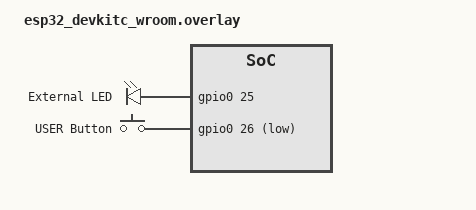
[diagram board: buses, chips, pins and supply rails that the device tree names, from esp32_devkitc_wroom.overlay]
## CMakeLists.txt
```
# SPDX-License-Identifier: Apache-2.0

cmake_minimum_required(VERSION 3.20.0)
find_package(Zephyr REQUIRED HINTS $ENV{ZEPHYR_BASE})
project(dronetag_task)

zephyr_include_directories(src)

target_sources(app PRIVATE 
            src/main.c
            src/my_led.c
            src/my_btn.c
            src/my_msgq.c
            src/my_fifo.c
            src/my_linked_list.c)
```

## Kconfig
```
# Config options for logger sample app

# Copyright (c) 2018 Nordic Semiconductor ASA
# SPDX-License-Identifier: Apache-2.0

mainmenu "Zephyr Application"

menu "Dronetag task configuration"

config MSGQ_SIZE
    int "Message Queue Size"
    default 10

endmenu

source "Kconfig.zephyr"
```

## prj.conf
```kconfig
CONFIG_PRINTK=y
CONFIG_SHELL=y
# CONFIG_LOG=y
# CONFIG_INIT_STACKS=y
# CONFIG_THREAD_STACK_INFO=y
# CONFIG_KERNEL_SHELL=y
# CONFIG_THREAD_MONITOR=y
# CONFIG_BOOT_BANNER=n
# CONFIG_THREAD_NAME=y
# CONFIG_DEVICE_SHELL=y
# CONFIG_POSIX_CLOCK=y
# CONFIG_DATE_SHELL=y
# CONFIG_THREAD_RUNTIME_STATS=y
# CONFIG_THREAD_RUNTIME_STATS_USE_TIMING_FUNCTIONS=y
# CONFIG_STATS=y
# CONFIG_STATS_SHELL=y

CONFIG_SHELL_CMDS=y
CONFIG_GPIO=y
```

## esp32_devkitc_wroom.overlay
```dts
/ {
    aliases {
        led0 = &external_led;
		userbtn = &user_button;
    };

    leds {
		compatible = "gpio-leds";

		external_led: led_0 {
			label = "External LED";
			gpios = <&gpio0 25 GPIO_ACTIVE_HIGH>;
		};
	};

	buttons {
		compatible = "gpio-keys";
		user_button: button_26 {
			gpios = <&gpio0 26 (GPIO_PULL_UP | GPIO_ACTIVE_LOW)>;
			label = "USER Button";
		};
	};
};
```

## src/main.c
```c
/*
 * Copyright (c) 2015 Intel Corporation
 *
 * SPDX-License-Identifier: Apache-2.0
 */

#include <zephyr/shell/shell.h>
#include <stdlib.h>

#include "my_led.h"
#include "my_btn.h"
#include "my_msgq.h"
#include "my_fifo.h"
#include "my_linked_list.h"

static int led_on(const struct shell *sh, size_t argc, char **argv);
static int led_off(const struct shell *sh, size_t argc, char **argv);
static int led_toggle(const struct shell *sh, size_t argc, char **argv);

static int write_static_to_msgq(const struct shell *sh, size_t argc, char **argv);
static int read_from_msgq(const struct shell *sh, size_t argc, char **argv);

static int push_data_to_fifo(const struct shell *sh, size_t argc, char **argv);
static int get_data_from_fifo(const struct shell *sh, size_t argc, char **argv);

static int append_data_to_linked_list(const struct shell *sh, size_t argc, char **argv);
static int get_last_data_from_linked_list(const struct shell *sh, size_t argc, char **argv);

static int led_on(const struct shell *sh, size_t argc, char **argv)
{
    ARG_UNUSED(argc);
    ARG_UNUSED(argv);

    my_led_on();
    shell_print(sh, "Led ON");
    return 0;
}

static int led_off(const struct shell *sh, size_t argc, char **argv)
{
    ARG_UNUSED(argc);
    ARG_UNUSED(argv);

    my_led_off();
    shell_print(sh, "Led OFF");
    return 0;
}

static int led_toggle(const struct shell *sh, size_t argc, char **argv)
{
    static int period = 1000;

    if (argc > 1)
    {
        period = atoi(argv[1]);
    }

    if (period <= 0)
    {
        shell_print(sh, "Invalid period!");
        return -EINVAL;
    }

    my_led_toggle(period);
    shell_print(sh, "Flashing LED with period %d ms", period);
    return 0;
}

static int write_static_to_msgq(const struct shell *sh, size_t argc, char **argv)
{
    ARG_UNUSED(argc);
    ARG_UNUSED(argv);

    if (my_msgq_write_static() != 0)
    {
        shell_print(sh, "MSGQ is full!");
        return 1;
    }

    shell_print(sh, "Message written to MSGQ");
    return 0;
}

static int read_from_msgq(const struct shell *sh, size_t argc, char **argv)
{
    ARG_UNUSED(argc);
    ARG_UNUSED(argv);
    static char *msg;

    msg = my_msgq_read();

    if (msg == NULL)
    {
        shell_print(sh, "MSGQ empty!");
        return 1;
    }

    shell_print(sh, "Received from MSGQ: '%s'", msg);
    return 0;
}

static int push_data_to_fifo(const struct shell *sh, size_t argc, char **argv)
{
    static int ret;
    static char *input_arg;

    if (argc <= 1)
    {
        shell_print(sh, "Missing input argument!");
        return 1;
    }

    ret = my_fifo_alloc_and_push_data(argv[1], strlen(argv[1]));

    if (ret == 0)
    {
        shell_print(sh, "Pushed '%s' into FIFO", argv[1]);
        return 0;
    }

    shell_print(sh, "Failed to allocate memory!");
    return 1;
}

static int get_data_from_fifo(const struct shell *sh, size_t argc, char **argv)
{
    char **data = NULL;
    data = my_fifo_get_data();

    if (data == NULL)
    {
        shell_print(sh, "FIFO is empty!");
        return 1;
    }

    shell_print(sh, "Received '%s' from FIFO", *data);
    my_fifo_free_data(data);
    return 0;
}

static int append_data_to_linked_list(const struct shell *sh, size_t argc, char **argv)
{
    static char msg[] = "dynamic";
    int size_appended = my_linked_list_alloc_and_append_data(msg);

    if (size_appended <= 0)
    {
        shell_print(sh, "Failed to allocate slab memory!");
        return 1;
    }

    if (size_appended == strlen(msg))
    {
        shell_print(sh, "Appended '%s' at the end of the linked list", msg);
        return 0;
    }

    msg[size_appended] = '\0';
    shell_print(sh, "Appended '%s' (truncated) at the end of the linked list", msg);
    return 0;
}

static int get_last_data_from_linked_list(const struct shell *sh, size_t argc, char **argv)
{
    linked_list_item_data_t *item = NULL;
    item = my_linked_list_get_last_data();

    if (item == NULL)
    {
        shell_print(sh, "Linked list is empty!");
        return 1;
    }

    shell_print(sh, "Received '%s' from linked list", item->data);
    my_linked_list_free_data(item);
    return 0;
}

SHELL_STATIC_SUBCMD_SET_CREATE(
    led_subcmds,
    SHELL_CMD_ARG(on, NULL, "Turn LED on.", &led_on, 1, 0),
    SHELL_CMD_ARG(off, NULL, "Turn LED off.", &led_off, 1, 0),
    SHELL_CMD_ARG(toggle, NULL, "Toggle LED with given period (ms).", &led_toggle, 1, 1),
    SHELL_SUBCMD_SET_END);
SHELL_CMD_REGISTER(led, &led_subcmds, "Led control commands", NULL);

SHELL_STATIC_SUBCMD_SET_CREATE(
    msgq_subcmds,
    SHELL_CMD_ARG(write, NULL, "Write 'static' to MSGQ", write_static_to_msgq, 1, 0),
    SHELL_CMD_ARG(read, NULL, "Pick up and dump message from MSGQ", read_from_msgq, 1, 0),
    SHELL_SUBCMD_SET_END);
SHELL_CMD_REGISTER(msgq, &msgq_subcmds, "Message queue commands", NULL);

SHELL_STATIC_SUBCMD_SET_CREATE(
    fifo_subcmds,
    SHELL_CMD_ARG(push, NULL, "Write given message to FIFO", push_data_to_fifo, 1, 1),
    SHELL_CMD_ARG(read, NULL, "Pick up and dump message from FIFO", get_data_from_fifo, 1, 0),
    SHELL_SUBCMD_SET_END);
SHELL_CMD_REGISTER(fifo, &fifo_subcmds, "FIFO commands", NULL);

SHELL_STATIC_SUBCMD_SET_CREATE(
    linked_list_subcmds,
    SHELL_CMD_ARG(append, NULL, "Append message at the end of linked list", append_data_to_linked_list, 1, 0),
    SHELL_CMD_ARG(read_last, NULL, "Read last message from linked list", get_last_data_from_linked_list, 1, 0),
    SHELL_SUBCMD_SET_END);
SHELL_CMD_REGISTER(linked_list, &linked_list_subcmds, "Linked list commands", NULL);

int main(void)
{
    int ret;

    ret = my_led_init();
    if (ret != 0)
    {
        return 0;
    }

    ret = my_btn_init();
    if (ret != 0)
    {
        return 0;
    }

    return 0;
}
```

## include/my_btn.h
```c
#ifndef _MY_BTN_H
#define _MY_BTN_H

int my_btn_init(void);

#endif
```

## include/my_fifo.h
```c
#ifndef _MY_FIFO_H
#define _MY_FIFO_H

#include <stddef.h>

int my_fifo_alloc_and_push_data(char *data, size_t len);
char **my_fifo_get_data(void);
void my_fifo_free_data(char **data);

#endif
```

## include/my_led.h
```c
#ifndef _MY_LED_H
#define _MY_LED_H

#include <zephyr/shell/shell.h>

int my_led_init(void);
int my_led_led_on(const struct shell *sh, size_t argc, char **argv);
int my_led_led_off(const struct shell *sh, size_t argc, char **argv);
int my_led_led_toggle(const struct shell *sh, size_t argc, char **argv);

#endif
```

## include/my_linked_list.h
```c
#ifndef _MY_LINKED_LIST_H
#define _MY_LINKED_LIST_H

#define LINKED_LIST_DATA_ITEM_SIZE 16

typedef struct
{
    char data[LINKED_LIST_DATA_ITEM_SIZE];
} linked_list_item_data_t;

int my_linked_list_alloc_and_append_data(const char *data);
linked_list_item_data_t *my_linked_list_get_last_data(void);
void my_linked_list_free_data(linked_list_item_data_t *data);

#endif
```

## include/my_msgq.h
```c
#ifndef _MY_MSGQ_H
#define _MY_MSGQ_H

#include <stddef.h>
#include <zephyr/shell/shell.h>

#define MSG_SIZE    16
#define MSGQ_SIZE   CONFIG_MSGQ_SIZE

extern struct k_msgq static_msgq;

int my_msgq_write_static(const struct shell *sh, size_t argc, char **argv);
int my_msgq_read(const struct shell *sh, size_t argc, char **argv);

#endif
```

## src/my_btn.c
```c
#include "my_btn.h"
#include <zephyr/kernel.h>
#include <zephyr/drivers/gpio.h>

#define SW0_NODE DT_ALIAS(userbtn)

static void button_pressed(const struct device *dev, struct gpio_callback *cb, uint32_t pins);
static void button_debounce(struct k_work *work);

static const struct gpio_dt_spec button = GPIO_DT_SPEC_GET_OR(SW0_NODE, gpios, {0});
static struct gpio_callback button_cb_data;
static struct k_work_delayable button_work;

int my_btn_init(void)
{
    int ret;

    if (!gpio_is_ready_dt(&button))
    {
        printk("Error: button device %s is not ready\n", button.port->name);
        return 1;
    }
    ret = gpio_pin_configure_dt(&button, GPIO_INPUT);
    if (ret != 0)
    {
        printk("Error %d: failed to configure %s pin %d\n",
               ret, button.port->name, button.pin);
        return 1;
    }

    ret = gpio_pin_interrupt_configure_dt(&button, GPIO_INT_EDGE_FALLING);
    if (ret != 0)
    {
        printk("Error %d: failed to configure interrupt on %s pin %d\n",
               ret, button.port->name, button.pin);
        return 1;
    }

    gpio_init_callback(&button_cb_data, button_pressed, BIT(button.pin));
    gpio_add_callback(button.port, &button_cb_data);

    k_work_init_delayable(&button_work, button_debounce);
    return 0;
}

static void button_pressed(const struct device *dev, struct gpio_callback *cb, uint32_t pins)
{
    k_work_reschedule(&button_work, K_MSEC(120));
}
static void button_debounce(struct k_work *work)
{
    ARG_UNUSED(work);

    printk("Button pressed\n");
}
```

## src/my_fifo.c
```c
#include "my_fifo.h"
#include <zephyr/kernel.h>
#include <string.h>

typedef struct
{
    void *fifo_reserved; /* 1st word reserved for use by FIFO */
    char *msg;
} fifo_item_t;

K_FIFO_DEFINE(dynamic_fifo);
K_HEAP_DEFINE(h, 256);

int my_fifo_alloc_and_push_data(char *data, size_t len)
{
    static fifo_item_t *tx_data_item = NULL;

    tx_data_item = k_heap_alloc(&h, sizeof(fifo_item_t), K_NO_WAIT); // alloc memory for data item
    if (tx_data_item == NULL)
    {
        return 1;
    }

    tx_data_item->msg = NULL;
    tx_data_item->msg = k_heap_alloc(&h, len + 1, K_NO_WAIT); // alloc memory for message
    if (tx_data_item->msg == NULL)
    {
        return 1;
    }

    tx_data_item->msg[len] = '\0';
    strncpy(tx_data_item->msg, data, len);
    k_fifo_put(&dynamic_fifo, tx_data_item);
    return 0;
}

char **my_fifo_get_data(void)
{
    static fifo_item_t *rx_data_item = NULL;
    rx_data_item = k_fifo_get(&dynamic_fifo, K_NO_WAIT);

    if (rx_data_item == NULL)
    {
        return NULL;
    }
    return &(rx_data_item->msg);
}

void my_fifo_free_data(char **data)
{
    fifo_item_t *item = NULL;
    item = CONTAINER_OF(data, fifo_item_t, msg);

    if (item != NULL)
    {
        k_heap_free(&h, item->msg);
        k_heap_free(&h, item);
    }
}
```

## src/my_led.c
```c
#include "my_led.h"
#include <zephyr/kernel.h>
#include <zephyr/drivers/gpio.h>

#define LED0_NODE DT_ALIAS(led0)

static void toggle_led(struct k_work *work);
static int set_led_state(int state);

static const struct gpio_dt_spec led = GPIO_DT_SPEC_GET(LED0_NODE, gpios);
static struct k_work_delayable led_work;
static struct k_work_sync led_sync;

static int led_state = 0;
static int led_period = 1000;

int my_led_init(void)
{
    if (!gpio_is_ready_dt(&led))
    {
        return 1;
    }

    if (gpio_pin_configure_dt(&led, GPIO_OUTPUT_LOW) < 0)
    {
        return 1;
    }

    k_work_init_delayable(&led_work, toggle_led);
    return 0;
}

int my_led_on(void)
{
    return set_led_state(1);
}

int my_led_off(void)
{

    return set_led_state(0);
}

int my_led_toggle(int ms)
{
    led_period = ms;
    if (led_period <= 0)
    {
        return 1;
    }

    k_work_reschedule(&led_work, K_NO_WAIT);
    return 0;
}

static void toggle_led(struct k_work *work)
{
    ARG_UNUSED(work);

    if (led_state == 0)
    {
        gpio_pin_set_dt(&led, 1);
        led_state = 1;
    }
    else
    {
        gpio_pin_set_dt(&led, 0);
        led_state = 0;
    }

    k_work_reschedule(&led_work, K_MSEC(led_period));
}

static int set_led_state(int state)
{
    k_work_cancel_delayable_sync(&led_work, &led_sync);

    gpio_pin_set_dt(&led, state);
    led_state = state;
    return 0;
}
```

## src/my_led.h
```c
#ifndef _MY_LED_H
#define _MY_LED_H

int my_led_init(void);
int my_led_on(void);
int my_led_off(void);
int my_led_toggle(int ms);

#endif
```

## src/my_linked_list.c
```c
#include "my_linked_list.h"
#include <zephyr/kernel.h>
#include <string.h>

typedef struct
{
    sys_snode_t node;
    linked_list_item_data_t msg;
} linked_list_item_t;

#define NECESSARY_LINKAGE_BYTES 4 // First 4 bytes of each unused block provide the necessary linkage.
#define MEM_BLOCKS_SIZE (LINKED_LIST_DATA_ITEM_SIZE + NECESSARY_LINKAGE_BYTES)
#define MEM_BLOCKS_AMOUNT 8
#define MEM_BUFFER_ALIGNMENT 4

K_MEM_SLAB_DEFINE(s, MEM_BLOCKS_SIZE, MEM_BLOCKS_AMOUNT, MEM_BUFFER_ALIGNMENT);
static sys_slist_t list = SYS_SLIST_STATIC_INIT(list);

int my_linked_list_alloc_and_append_data(const char *data)
{
    void *tmp = NULL;

    if (k_mem_slab_alloc(&s, &tmp, K_NO_WAIT) != 0)
    {
        return 0;
    }

    linked_list_item_t *item = (linked_list_item_t *)tmp;
    if ((strlen(data) + 1) > LINKED_LIST_DATA_ITEM_SIZE)
    {
        strncpy(item->msg.data, data, LINKED_LIST_DATA_ITEM_SIZE - 1);
        item->msg.data[LINKED_LIST_DATA_ITEM_SIZE - 1] = '\0';
    }
    else
    {
        strncpy(item->msg.data, data, strlen(data));
        item->msg.data[strlen(data)] = '\0';
    }

    sys_slist_append(&list, &item->node);
    return strlen(item->msg.data);
}

linked_list_item_data_t *my_linked_list_get_last_data(void)
{
    linked_list_item_t *item = NULL;
    sys_snode_t *tmp;
    tmp = sys_slist_peek_tail(&list);

    if (tmp == NULL)
    {
        return NULL;
    }

    item = CONTAINER_OF(tmp, linked_list_item_t, node);
    return &(item->msg);
}

void my_linked_list_free_data(linked_list_item_data_t *data)
{
    linked_list_item_t *item = NULL;
    item = CONTAINER_OF(data, linked_list_item_t, msg);

    sys_slist_find_and_remove(&list, &item->node);
    k_mem_slab_free(&s, item);
}
```

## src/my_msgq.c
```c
#include "my_msgq.h"
#include <zephyr/kernel.h>

K_MSGQ_DEFINE(static_msgq, MSG_SIZE, MSGQ_SIZE, 1);

int my_msgq_write_static(void)
{
    const char message[] = "static";

    if (k_msgq_put(&static_msgq, message, K_NO_WAIT) != 0)
    {
        return 1;
    }
    return 0;
}

char *my_msgq_read(void)
{
    static char msg[MSG_SIZE];

    if (k_msgq_get(&static_msgq, msg, K_NO_WAIT) != 0)
    {
        return NULL;
    }
    return msg;
}
```

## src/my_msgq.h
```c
#ifndef _MY_MSGQ_H
#define _MY_MSGQ_H

#define MSG_SIZE    16
#define MSGQ_SIZE   CONFIG_MSGQ_SIZE

int my_msgq_write_static(void);
char *my_msgq_read(void);

#endif
```
